# EFR32FG1V131F256GM48 register map
File version: 3.0.0
CPU: CM4 r0p1, little endian, MPU, FPU, 3 interrupt priority bits
Registers are 32-bit, read-write, reset 0x0 unless marked. A register's access mark holds for its fields unless they carry their own. Offsets are from the block's base; [hi:lo] are bit positions; {n}, {i} and the like mark numbered series; 'fields as' and 'values as' point back to an identical list.

## PROTIMER
Base 0x40085000
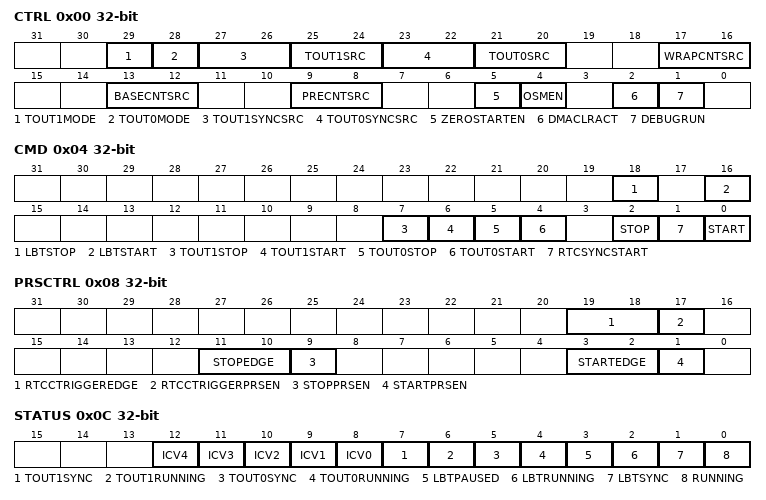
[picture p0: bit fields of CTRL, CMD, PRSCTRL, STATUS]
0x00 CTRL
  [29] TOUT1MODE — Repeat Mode
  [28] TOUT0MODE — Repeat Mode
  [27:26] TOUT1SYNCSRC
  [25:24] TOUT1SRC
  [23:22] TOUT0SYNCSRC
  [21:20] TOUT0SRC
  [17:16] WRAPCNTSRC
  [13:12] BASECNTSRC
  [9:8] PRECNTSRC — Selects clock to Pre-counter
  [5] ZEROSTARTEN — Start from zero enable
  [4] OSMEN — One-Shot Mode Enable
  [2] DMACLRACT
  [1] DEBUGRUN
0x04 CMD wo
  [18] LBTSTOP
  [16] LBTSTART
  [7] TOUT1STOP
  [6] TOUT1START
  [5] TOUT0STOP
  [4] TOUT0START
  [2] STOP
  [1] RTCSYNCSTART — Start PROTIMER Synchronized with RTCC
  [0] START — Start PROTIMER
0x08 PRSCTRL
  [19:18] RTCCTRIGGEREDGE
  [17] RTCCTRIGGERPRSEN — Enable RTCC Trigger from PRS.
  [11:10] STOPEDGE
  [9] STOPPRSEN
  [3:2] STARTEDGE
  [1] STARTPRSEN
0x0C STATUS ro
  [n+8] ICV{n} (n=0..4), [7] TOUT1SYNC, [6] TOUT1RUNNING, [5] TOUT0SYNC, [4] TOUT0RUNNING, [3] LBTPAUSED, [2] LBTRUNNING, [1] LBTSYNC, [0] RUNNING
0x10 PRECNT
  [15:0] PRECNT
0x14 BASECNT
  [15:0] BASECNT
0x18 WRAPCNT
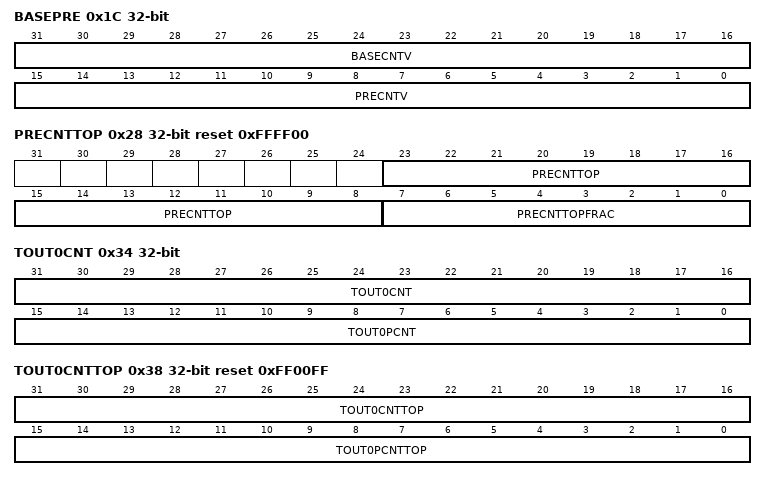
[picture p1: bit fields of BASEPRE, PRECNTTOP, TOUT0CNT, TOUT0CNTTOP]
0x1C BASEPRE ro
  [31:16] BASECNTV, [15:0] PRECNTV
0x20 LWRAPCNT ro
0x24 PRECNTTOPADJ
  [15:0] PRECNTTOPADJ
0x28 PRECNTTOP reset 0xFFFF00
  [23:8] PRECNTTOP, [7:0] PRECNTTOPFRAC
0x2C BASECNTTOP reset 0xFFFF
  [15:0] BASECNTTOP
0x30 WRAPCNTTOP
0x34 TOUT0CNT
  [31:16] TOUT0CNT, [15:0] TOUT0PCNT
0x38 TOUT0CNTTOP reset 0xFF00FF
  [31:16] TOUT0CNTTOP, [15:0] TOUT0PCNTTOP
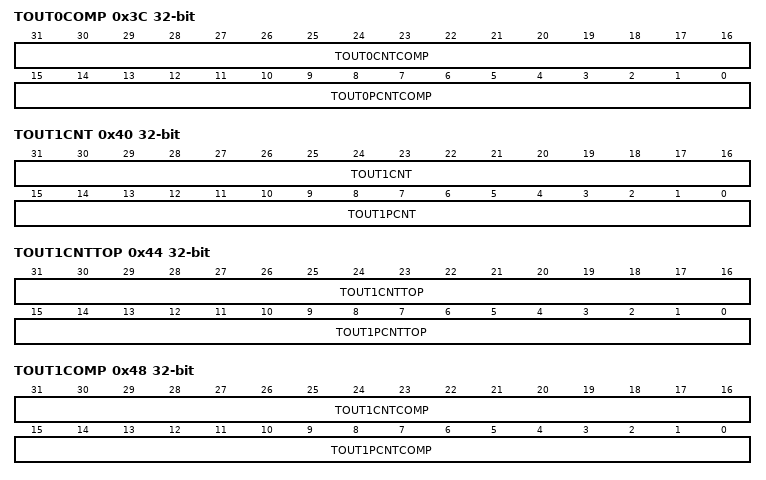
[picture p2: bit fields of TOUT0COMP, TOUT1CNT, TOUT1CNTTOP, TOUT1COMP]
0x3C TOUT0COMP
  [31:16] TOUT0CNTCOMP, [15:0] TOUT0PCNTCOMP
0x40 TOUT1CNT
  [31:16] TOUT1CNT, [15:0] TOUT1PCNT
0x44 TOUT1CNTTOP
  [31:16] TOUT1CNTTOP, [15:0] TOUT1PCNTTOP
0x48 TOUT1COMP
  [31:16] TOUT1CNTCOMP, [15:0] TOUT1PCNTCOMP
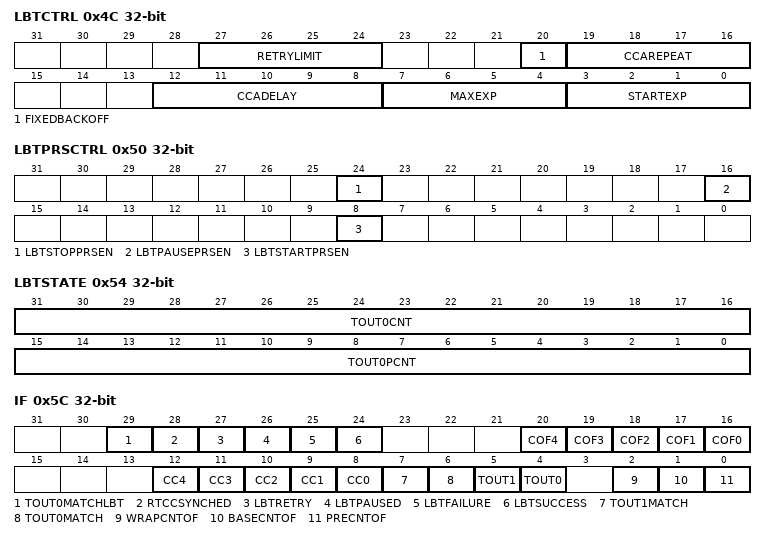
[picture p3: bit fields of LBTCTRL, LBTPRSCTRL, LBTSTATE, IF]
0x4C LBTCTRL
  [27:24] RETRYLIMIT, [20] FIXEDBACKOFF, [19:16] CCAREPEAT, [12:8] CCADELAY, [7:4] MAXEXP, [3:0] STARTEXP
0x50 LBTPRSCTRL
  [24] LBTSTOPPRSEN — Enable LBT stop commands from PRS.
  [16] LBTPAUSEPRSEN — Enable LBT pause commands from PRS.
  [8] LBTSTARTPRSEN
0x54 LBTSTATE ro
  [31:16] TOUT0CNT rw — TOUT0CNT value to be saved
  [15:0] TOUT0PCNT rw — TOUT0PCNT value to be saved
0x58 RANDOM
  [15:0] RANDOM
0x5C IF ro
  [29] TOUT0MATCHLBT — TOUT0 compare match interrupt flag
  [28] RTCCSYNCHED — PROTIMER synchronized with the RTCC
  [27] LBTRETRY — Listen Before Talk Retry
  [26] LBTPAUSED — Listen Before Talk Paused
  [25] LBTFAILURE — Listen Before Talk Failure
  [24] LBTSUCCESS — Listen Before Talk Success
  [n+16] COF{n} (n=0..4) — CC Channel {n} Overflow Interrupt Flag
  [n+8] CC{n} (n=0..4) — CC Channel {n} Interrupt Flag
  [7] TOUT1MATCH — TOUT1 compare match interrupt flag
  [6] TOUT0MATCH — TOUT0 compare match interrupt flag
  [5] TOUT1 — TOUT1 underflow interrupt flag
  [4] TOUT0 — TOUT0 underflow interrupt flag
  [2] WRAPCNTOF — WRAPCNT Overflow Interrupt Flag
  [1] BASECNTOF — BASECNT Overflow Interrupt Flag
  [0] PRECNTOF — PRECNT Overflow Interrupt Flag
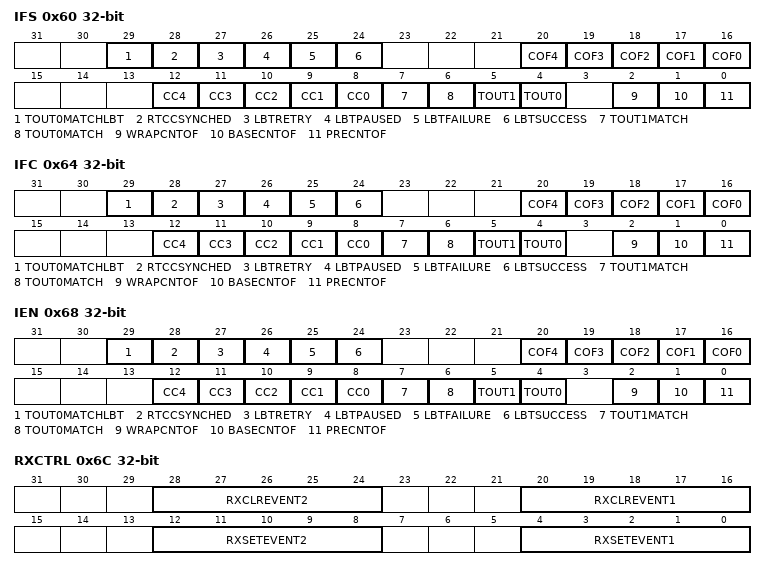
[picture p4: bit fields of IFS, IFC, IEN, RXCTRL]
0x60 IFS wo
  [29] TOUT0MATCHLBT rw — TOUT0MATCHLBT Interrupt Enable
  [28] RTCCSYNCHED — RTCCSYNCHED Interrupt Enable
  [27] LBTRETRY — LBTRETRY Interrupt Enable
  [26] LBTPAUSED — LBTPAUSED Interrupt Enable
  [25] LBTFAILURE — LBTFAILURE Interrupt Enable
  [24] LBTSUCCESS — LBTSUCCESS Interrupt Enable
  [n+16] COF{n} (n=0..4) — COF{n} Interrupt Enable
  [n+8] CC{n} (n=0..4) — CC{n} Interrupt Enable
  [7] TOUT1MATCH — TOUT1MATCH Interrupt Enable
  [6] TOUT0MATCH — TOUT0MATCH Interrupt Enable
  [5] TOUT1 — TOUT1 Interrupt Enable
  [4] TOUT0 — TOUT0 Interrupt Enable
  [2] WRAPCNTOF — WRAPCNTOF Interrupt Enable
  [1] BASECNTOF — BASECNTOF Interrupt Enable
  [0] PRECNTOF — PRECNTOF Interrupt Enable
0x64 IFC wo
  fields as IFS
0x68 IEN
  [29] TOUT0MATCHLBT — TOUT0MATCHLBT Interrupt Enable
  [28] RTCCSYNCHED — RTCCSYNCHED Interrupt Enable
  [27] LBTRETRY — LBTRETRY Interrupt Enable
  [26] LBTPAUSED — LBTPAUSED Interrupt Enable
  [25] LBTFAILURE — LBTFAILURE Interrupt Enable
  [24] LBTSUCCESS — LBTSUCCESS Interrupt Enable
  [n+16] COF{n} (n=0..4) — COF{n} Interrupt Enable
  [n+8] CC{n} (n=0..4) — CC{n} Interrupt Enable
  [7] TOUT1MATCH — TOUT1MATCH Interrupt Enable
  [6] TOUT0MATCH — TOUT0MATCH Interrupt Enable
  [5] TOUT1 — TOUT1 Interrupt Enable
  [4] TOUT0 — TOUT0 Interrupt Enable
  [2] WRAPCNTOF — WRAPCNTOF Interrupt Enable
  [1] BASECNTOF — BASECNTOF Interrupt Enable
  [0] PRECNTOF — PRECNTOF Interrupt Enable
0x6C RXCTRL
  [28:24] RXCLREVENT2 — Second event that clears RX req signal
  [20:16] RXCLREVENT1 — First event that clears RX req signal
  [12:8] RXSETEVENT2 — Second event that sets RX req signal
  [4:0] RXSETEVENT1 — First event that sets RX req signal
    0=DISABLED (Request is never set); 1=ALWAYS (Does not wait for any particular event); 2=PRECNTOF (Pre counter overflow); 3=BASECNTOF (Base counter overflow); 4=WRAPCNTOF (Wrap counter overflow); 5=TOUT0UF (Timeout counter 0 underflow); 6=TOUT1UF (Timeout counter 1 underflow); 7=TOUT0MATCH (Timeout counter 0 match); 8=TOUT1MATCH (Timeout counter 1 match); {v}=CC{v-9} (Channel {v-9} Capture/Compare event) (v=9..13); 14=TXDONE (MOD indicated that TX completed); 15=RXDONE (FRC indicated that RX completed); 16=TXORRXDONE (MOD/FRC indicated that TX or RX completed); 17=FDET0 (DEMOD indicated that syncword 0 was detected); 18=FDET1 (DEMOD indicated that syncword 1 was detected); 19=FDET0OR1 (DEMOD indicated that syncword 0 or 1 was detected); 20=LBTSUCCESS (LBT completed successfully); 21=LBTRETRY (LBT detected occupied channel and will try again); 22=LBTFAILURE (LBT could not start transmission); 23=ANYLBT (Any LBT event); 24=CCAACK (A CCA measurement completed); 25=CCA (A CCA measurement completed, and channel was clear); 26=NOTCCA (A CCA measurement completed, and channel was busy); 27=TOUT0MATCHLBT (Timeout counter 0 match occurred during LBT operation)
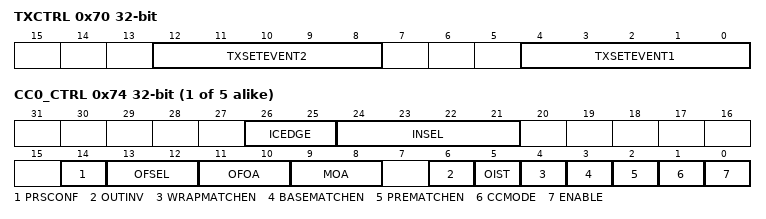
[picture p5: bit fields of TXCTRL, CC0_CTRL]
0x70 TXCTRL
  [12:8] TXSETEVENT2 — Second event that sets TX req signal
  [4:0] TXSETEVENT1 — First event that sets TX req signal
    values as RXCTRL.RXSETEVENT1
{0x74+0x10*i} CC{i}_CTRL (i=0..4)
  [26:25] ICEDGE — Input Capture Edge Select
    0=RISING (Rising edges detected); 1=FALLING (Falling edges detected); 2=BOTH (Both edges detected); 3=DISABLED (No edge detection, signal is left as it is)
  [24:21] INSEL — Capture input selection
    0=PRS (Use the selected PRS channel); 1=TXDONE (TX completed); 2=RXDONE (RX completed); 3=TXORRXDONE (TX or RX completed); 4=FRAMEDET0 (Demodulator found sync word 0); 5=FRAMEDET1 (Demodulator found sync word 1); 6=FDET0OR1 (Demodulator found sync word 0 or 1); 7=MODSYNCSENT (Modulator sync word sent); 8=RXEOF (RX at end of frame from demodulator); 9=PRORTC0 (PRORTC capture/compare 0); 10=PRORTC1 (PRORTC capture/compare 1)
  [14] PRSCONF — PRS Configuration
    0=PULSE (Each CC event will generate a one HFRADIOCLK cycle high pulse); 1=LEVEL (Should be used when OFSEL, OFOA or MOA are specified.)
  [13:12] OFSEL — Select counter for OFOA bits
    0=PRECNT (Use PRECNT overflow); 1=BASECNT (Use BASECNT overflow); 2=WRAPCNT (Use WRAPCNT overflow); 3=DISABLED
  [11:10] OFOA — Overflow Output Action
    0=DISABLED (No action); 1=TOGGLE (Toggle output when the selected counter has an overflow event.); 2=CLEAR (Clear output when the selected counter has an overflow event.); 3=SET (Set output when the selected counter has an overflow event.)
  [9:8] MOA — Match Output Action
    0=DISABLED (No action on compare match); 1=TOGGLE (Toggle output on compare match in COMPARE mode.); 2=CLEAR (Clear output on compare match in COMPARE mode.); 3=SET (Set output on compare match in COMPARE mode.)
  [6] OUTINV — Output Invert
  [5] OIST — Output Initial State
  [4] WRAPMATCHEN — Enable WRAPCNT matching
  [3] BASEMATCHEN — Enable BASECNT matching
  [2] PREMATCHEN — Enable PRECNT matching
  [1] CCMODE — Compare/Capture mode
    0=COMPARE (Compare mode selected); 1=CAPTURE (Capture mode selected)
  [0] ENABLE — Channel Enable
{0x78+0x10*i} CC{i}_PRE (i=0..4)
  [15:0] PRE — CC Channel PRE Value
{0x7C+0x10*i} CC{i}_BASE (i=0..4)
  [15:0] BASE — CC Channel BASE Value
{0x80+0x10*i} CC{i}_WRAP (i=0..4)
  [31:0] WRAP — CC Channel WRAP Value

## PROTIMER_CLR — PROTIMER
Base 0x44085000
Same registers: PROTIMER_SET 0x46085000
Registers as PROTIMER; these are added or differ:
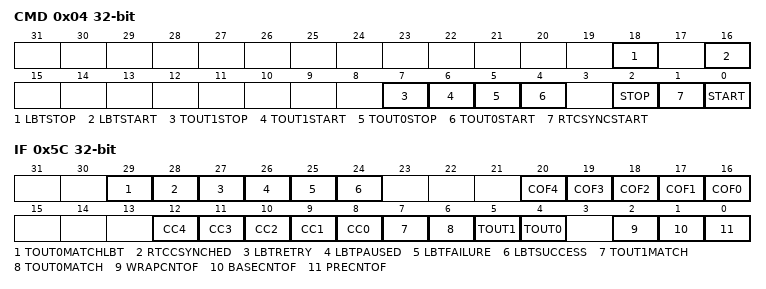
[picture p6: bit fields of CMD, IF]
0x04 CMD wo
  [18] LBTSTOP
  [16] LBTSTART
  [7] TOUT1STOP
  [6] TOUT1START
  [5] TOUT0STOP
  [4] TOUT0START
  [2] STOP
  [1] RTCSYNCSTART — Start PROTIMER Synchronized with RTCC
  [0] START — Start PROTIMER
0x5C IF ro
  fields as PROTIMER.IF
